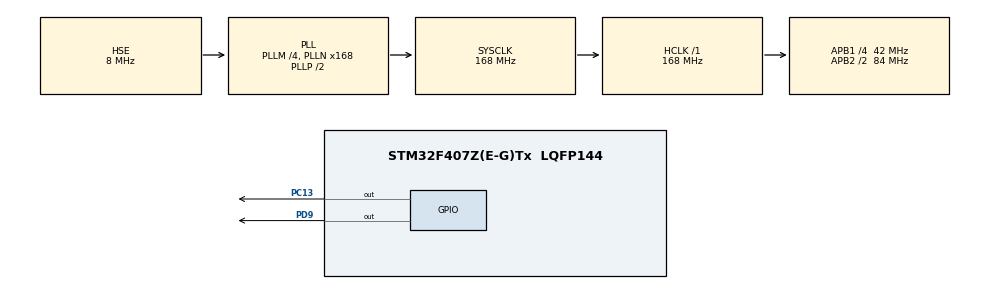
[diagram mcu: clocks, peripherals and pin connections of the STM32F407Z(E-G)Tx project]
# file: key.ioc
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Mcu.Family=STM32F4
Mcu.Name=STM32F407Z(E-G)Tx
Mcu.Package=LQFP144
NVIC.PriorityGroup=NVIC_PRIORITYGROUP_4
PA13.Mode=Serial_Wire
PA13.Signal=SYS_JTMS-SWDIO
PA14.Mode=Serial_Wire
PA14.Signal=SYS_JTCK-SWCLK
PC13-ANTI_TAMP.Signal=GPIO_Output
PC14-OSC32_IN.Mode=LSE-External-Oscillator
PC14-OSC32_IN.Signal=RCC_OSC32_IN
PC15-OSC32_OUT.Mode=LSE-External-Oscillator
PC15-OSC32_OUT.Signal=RCC_OSC32_OUT
PD9.Signal=GPIO_Output
PH0-OSC_IN.Mode=HSE-External-Oscillator
PH0-OSC_IN.Signal=RCC_OSC_IN
PH1-OSC_OUT.Mode=HSE-External-Oscillator
PH1-OSC_OUT.Signal=RCC_OSC_OUT
ProjectManager.HeapSize=0x200
ProjectManager.StackSize=0x400
ProjectManager.TargetToolchain=MDK-ARM V5.32
RCC.48MHZClocksFreq_Value=84000000
RCC.AHBFreq_Value=168000000
RCC.APB1CLKDivider=RCC_HCLK_DIV4
RCC.APB1Freq_Value=42000000
RCC.APB1TimFreq_Value=84000000
RCC.APB2CLKDivider=RCC_HCLK_DIV2
RCC.APB2Freq_Value=84000000
RCC.APB2TimFreq_Value=168000000
RCC.CortexFreq_Value=168000000
RCC.HCLKFreq_Value=168000000
RCC.HSE_VALUE=8000000
RCC.HSI_VALUE=16000000
RCC.PLLM=4
RCC.PLLN=168
RCC.PLLSourceVirtual=RCC_PLLSOURCE_HSE
RCC.SYSCLKFreq_VALUE=168000000
RCC.SYSCLKSource=RCC_SYSCLKSOURCE_PLLCLK
RCC.VCOOutputFreq_Value=336000000
board=custom

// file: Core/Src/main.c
/* USER CODE BEGIN Header */
/**
  ******************************************************************************
  * @file           : main.c
  * @brief          : Main program body
  ******************************************************************************
  * @attention
  *
  * Copyright (c) 2026 STMicroelectronics.
  * All rights reserved.
  *
  * This software is licensed under terms that can be found in the LICENSE file
  * in the root directory of this software component.
  * If no LICENSE file comes with this software, it is provided AS-IS.
  *
  ******************************************************************************
  */
/* USER CODE END Header */
#include "main.h"

/* USER CODE BEGIN Includes */
#include "bsp_gpio.h"
#include "bsp_key.h"
#include "bsp_tim.h"
#include "bsp_uart.h"
#include "ring_buff.h"
#include <string.h>

/* USER CODE END Includes */

void SystemClock_Config(void);
static void MX_GPIO_Init(void);

int main(void)
{

  /* MCU Configuration--------------------------------------------------------*/

  /* Reset of all peripherals, Initializes the Flash interface and the Systick. */
  HAL_Init();

  /* Configure the system clock */
  SystemClock_Config();

  /* Initialize all configured peripherals */
//  MX_GPIO_Init();
  /* USER CODE BEGIN 2 */

  BspLed_Init();
  Bsp_Key_Init();
  Bsp_Tim_Init();
  BspUart_Init();
  uint8_t frame[UART_RX_BUF_SIZE];
  extern stRingBufTdf s_rx;

  /* USER CODE END 2 */

  /* Infinite loop */
  /* USER CODE BEGIN WHILE */
  while (1)
  {

//uint8_t e1 = Key_Check(KEY_1, KEY_SINGLE);
//uint8_t e2 = Key_Check(KEY_2, KEY_SINGLE);
//if (e1 | e2)          /* 用位或，两边都会执行 */
//    BspLed_On();

//		if (Key_Check(KEY_1, KEY_SINGLE)||Key_Check(KEY_2, KEY_SINGLE) )
//		{
//			BspLed_On();
//		}
//		if (Key_Check(KEY_1, KEY_DOUBLE) || Key_Check(KEY_2, KEY_DOUBLE))
//		{
//			BspLed_Off();
//		}
//		if (Key_Check(KEY_1, KEY_LONG) || Key_Check(KEY_2, KEY_LONG)||Key_Check(KEY_1, KEY_REPEAT) || Key_Check(KEY_2, KEY_REPEAT))
//		{
//			BspLed_Toggle();
//		}

    uint8_t sing = 0, dbl = 0, lng = 0;

    for (uint8_t k = KEY_1; k <= KEY_2; k++)
    {
        sing |= Key_Check(k, KEY_SINGLE);
        dbl  |= Key_Check(k, KEY_DOUBLE);
        lng  |= Key_Check(k, KEY_LONG) | Key_Check(k, KEY_REPEAT);
    }

    if (sing) BspLed_On();
    if (dbl)  BspLed_Off();
    if (lng)  BspLed_Toggle();
////	  BspUart_SendByte(g_rx_byte);   /* 只打印"最后一个字节" */
//////    HAL_Delay(100);
    if (g_frame_ready)                            /* M3 */
    {
        uint32_t n = g_frame_len;                 /* M5 先快照 */
        g_frame_ready = 0;                        /* M6 尽早清标志 */

        if (n >= sizeof(frame))                   /* M8 截断保护 */
            n = sizeof(frame) - 1U;

        uint32_t got = 0;
        for (uint32_t i = 0; i < n; i++)          /* M10 */
        {
            uint8_t c;
            if (ucRingBufRead(&s_rx, &c) != 0)    /* M13 0=成功 */
                break;
            frame[got++] = c;
        }
        frame[got] = 0;                           /* M18 补结束符 */

        BspUart_SendString((const char *)frame);  /* M20 */
        BspUart_SendString("\r\n");               /* M21 */
    }

}

    /* USER CODE END WHILE */

  }

void SystemClock_Config(void)
{
  RCC_OscInitTypeDef RCC_OscInitStruct = {0};
  RCC_ClkInitTypeDef RCC_ClkInitStruct = {0};

  /** Configure the main internal regulator output voltage
  */
  __HAL_RCC_PWR_CLK_ENABLE();
  __HAL_PWR_VOLTAGESCALING_CONFIG(PWR_REGULATOR_VOLTAGE_SCALE1);

  /** Initializes the RCC Oscillators according to the specified parameters
  * in the RCC_OscInitTypeDef structure.
  */
  RCC_OscInitStruct.OscillatorType = RCC_OSCILLATORTYPE_HSE;
  RCC_OscInitStruct.HSEState = RCC_HSE_ON;
  RCC_OscInitStruct.PLL.PLLState = RCC_PLL_ON;
  RCC_OscInitStruct.PLL.PLLSource = RCC_PLLSOURCE_HSE;
  RCC_OscInitStruct.PLL.PLLM = 4;
  RCC_OscInitStruct.PLL.PLLN = 168;
  RCC_OscInitStruct.PLL.PLLP = RCC_PLLP_DIV2;
  RCC_OscInitStruct.PLL.PLLQ = 4;
  if (HAL_RCC_OscConfig(&RCC_OscInitStruct) != HAL_OK)
  {
    Error_Handler();
  }

  /** Initializes the CPU, AHB and APB buses clocks
  */
  RCC_ClkInitStruct.ClockType = RCC_CLOCKTYPE_HCLK|RCC_CLOCKTYPE_SYSCLK
                              |RCC_CLOCKTYPE_PCLK1|RCC_CLOCKTYPE_PCLK2;
  RCC_ClkInitStruct.SYSCLKSource = RCC_SYSCLKSOURCE_PLLCLK;
  RCC_ClkInitStruct.AHBCLKDivider = RCC_SYSCLK_DIV1;
  RCC_ClkInitStruct.APB1CLKDivider = RCC_HCLK_DIV4;
  RCC_ClkInitStruct.APB2CLKDivider = RCC_HCLK_DIV2;

  if (HAL_RCC_ClockConfig(&RCC_ClkInitStruct, FLASH_LATENCY_5) != HAL_OK)
  {
    Error_Handler();
  }
}

static void MX_GPIO_Init(void)
{
  GPIO_InitTypeDef GPIO_InitStruct = {0};

  /* GPIO Ports Clock Enable */
  __HAL_RCC_GPIOC_CLK_ENABLE();
  __HAL_RCC_GPIOH_CLK_ENABLE();
  __HAL_RCC_GPIOD_CLK_ENABLE();
  __HAL_RCC_GPIOA_CLK_ENABLE();

  /*Configure GPIO pin Output Level */
  HAL_GPIO_WritePin(GPIOC, GPIO_PIN_13, GPIO_PIN_RESET);

  /*Configure GPIO pin Output Level */
  HAL_GPIO_WritePin(GPIOD, GPIO_PIN_9, GPIO_PIN_RESET);

  /*Configure GPIO pin : PC13 */
  GPIO_InitStruct.Pin = GPIO_PIN_13;
  GPIO_InitStruct.Mode = GPIO_MODE_OUTPUT_PP;
  GPIO_InitStruct.Pull = GPIO_NOPULL;
  GPIO_InitStruct.Speed = GPIO_SPEED_FREQ_LOW;
  HAL_GPIO_Init(GPIOC, &GPIO_InitStruct);

  /*Configure GPIO pin : PD9 */
  GPIO_InitStruct.Pin = GPIO_PIN_9;
  GPIO_InitStruct.Mode = GPIO_MODE_OUTPUT_PP;
  GPIO_InitStruct.Pull = GPIO_NOPULL;
  GPIO_InitStruct.Speed = GPIO_SPEED_FREQ_LOW;
  HAL_GPIO_Init(GPIOD, &GPIO_InitStruct);

}

void Error_Handler(void)
{
  __disable_irq();
  while (1)
  {
  }
}
